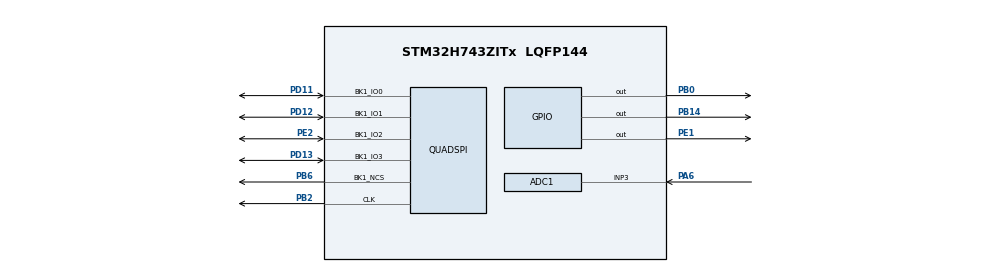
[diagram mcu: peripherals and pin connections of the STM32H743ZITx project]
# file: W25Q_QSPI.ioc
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ADC1.Channel-1\#ChannelRegularConversion=ADC_CHANNEL_3
ADC1.ClockPrescaler=ADC_CLOCK_ASYNC_DIV4
ADC1.NbrOfConversionFlag=1
ADC1.OffsetNumber-1\#ChannelRegularConversion=ADC_OFFSET_NONE
ADC1.OffsetSignedSaturation-1\#ChannelRegularConversion=DISABLE
ADC1.Rank-1\#ChannelRegularConversion=1
ADC1.Resolution=ADC_RESOLUTION_12B
ADC1.SamplingTime-1\#ChannelRegularConversion=ADC_SAMPLETIME_387CYCLES_5
ADC1.master=1
CORTEX_M7.AccessPermission_S-Cortex_Memory_Protection_Unit_Region1_Settings_S=MPU_REGION_FULL_ACCESS
CORTEX_M7.AccessPermission_Spec=MPU_REGION_FULL_ACCESS
CORTEX_M7.BaseAddress_S-Cortex_Memory_Protection_Unit_Region1_Settings_S=0x90000000
CORTEX_M7.BaseAddress_Spec=0x90000000
CORTEX_M7.CPU_DCache=Enabled
CORTEX_M7.CPU_ICache=Enabled
CORTEX_M7.Enable_S-Cortex_Memory_Protection_Unit_Region1_Settings_S=MPU_REGION_ENABLE
CORTEX_M7.IsBufferable_S-Cortex_Memory_Protection_Unit_Region1_Settings_S=MPU_ACCESS_BUFFERABLE
CORTEX_M7.IsBufferable_Spec=MPU_ACCESS_BUFFERABLE
CORTEX_M7.IsCacheable_S-Cortex_Memory_Protection_Unit_Region1_Settings_S=MPU_ACCESS_CACHEABLE
CORTEX_M7.IsCacheable_Spec=MPU_ACCESS_CACHEABLE
CORTEX_M7.IsShareable_Spec=MPU_ACCESS_NOT_SHAREABLE
CORTEX_M7.Size_S-Cortex_Memory_Protection_Unit_Region1_Settings_S=MPU_REGION_SIZE_1MB
CORTEX_M7.Size_Spec=MPU_REGION_SIZE_32MB
CORTEX_M7.SubRegionDisable_Spec=0
CORTEX_M7.default_mode_Activation=1
Mcu.Family=STM32H7
Mcu.Name=STM32H743ZITx
Mcu.Package=LQFP144
NUCLEO-H743ZI2.BUTTON=0
NUCLEO-H743ZI2.LD1=true
NUCLEO-H743ZI2.LD2=true
NUCLEO-H743ZI2.LD3=true
NUCLEO-H743ZI2.VCP=false
NVIC.PriorityGroup=NVIC_PRIORITYGROUP_4
PA13\ (JTMS/SWDIO).GPIO_Label=JTMS
PA13\ (JTMS/SWDIO).Signal=DEBUG_JTMS-SWDIO
PA14\ (JTCK/SWCLK).GPIO_Label=JTCK
PA14\ (JTCK/SWCLK).Signal=DEBUG_JTCK-SWCLK
PA6.Signal=ADCx_INP3
PB0.Signal=GPIO_Output
PB14.Signal=GPIO_Output
PB2.GPIO_Speed=GPIO_SPEED_FREQ_VERY_HIGH
PB2.Mode=Single Bank 1
PB2.Signal=QUADSPI_CLK
PB6.GPIO_Speed=GPIO_SPEED_FREQ_VERY_HIGH
PB6.Mode=Single Bank 1
PB6.Signal=QUADSPI_BK1_NCS
PC14-OSC32_IN\ (OSC32_IN).Signal=RCC_OSC32_IN
PC15-OSC32_OUT\ (OSC32_OUT).Signal=RCC_OSC32_OUT
PD11.GPIO_Speed=GPIO_SPEED_FREQ_VERY_HIGH
PD11.Mode=Single Bank 1
PD11.Signal=QUADSPI_BK1_IO0
PD12.GPIO_Speed=GPIO_SPEED_FREQ_VERY_HIGH
PD12.Mode=Single Bank 1
PD12.Signal=QUADSPI_BK1_IO1
PD13.GPIO_Speed=GPIO_SPEED_FREQ_VERY_HIGH
PD13.Mode=Single Bank 1
PD13.Signal=QUADSPI_BK1_IO3
PE1.Signal=GPIO_Output
PE2.GPIO_Speed=GPIO_SPEED_FREQ_VERY_HIGH
PE2.Mode=Single Bank 1
PE2.Signal=QUADSPI_BK1_IO2
PH0-OSC_IN\ (PH0).Mode=HSE-External-Oscillator
PH0-OSC_IN\ (PH0).Signal=RCC_OSC_IN
PH1-OSC_OUT\ (PH1).Mode=HSE-External-Oscillator
PH1-OSC_OUT\ (PH1).Signal=RCC_OSC_OUT
ProjectManager.HeapSize=0x200
ProjectManager.StackSize=0x400
ProjectManager.TargetToolchain=STM32CubeIDE
QUADSPI.ChipSelectHighTime=QSPI_CS_HIGH_TIME_1_CYCLE
QUADSPI.ClockPrescaler=1
QUADSPI.FifoThreshold=4
QUADSPI.FlashSize=24
QUADSPI.SampleShifting=QSPI_SAMPLE_SHIFTING_HALFCYCLE
RCC.ADCFreq_Value=75000000
RCC.APB1Freq_Value=100000000
RCC.APB2Freq_Value=100000000
RCC.APB3Freq_Value=100000000
RCC.APB4Freq_Value=100000000
RCC.CortexFreq_Value=400000000
RCC.D1PPRE=RCC_APB3_DIV2
RCC.D2PPRE1=RCC_APB1_DIV2
RCC.D2PPRE2=RCC_APB2_DIV2
RCC.D3PPRE=RCC_APB4_DIV2
RCC.DIVM1=2
RCC.DIVM2=2
RCC.DIVN1=64
RCC.DIVN2=12
RCC.DIVQ1=4
RCC.EnbaleCSS=true
RCC.HCLKFreq_Value=200000000
RCC.HPRE=RCC_HCLK_DIV2
RCC.PLL2FRACN=0
RCC.PLL3FRACN=0
RCC.PLLFRACN=0
RCC.PLLSourceVirtual=RCC_PLLSOURCE_HSE
RCC.SYSCLKFreq_VALUE=400000000
RCC.SYSCLKSource=RCC_SYSCLKSOURCE_PLLCLK
RCC.USBFreq_Value=200000000
SH.ADCx_INP3.0=ADC1_INP3,IN3-Single-Ended
VP_MEMORYMAP_VS_MEMORYMAP.Mode=CurAppReg
VP_NUCLEO-H743ZI2_VS_BSP_COMMON.Mode=COMMON
board=NUCLEO-H743ZI2

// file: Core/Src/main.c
/* USER CODE BEGIN Header */
/* USER CODE END Header */
#include "main.h"
#include "adc.h"
#include "quadspi.h"
#include "gpio.h"

/* USER CODE BEGIN Includes */
#include "quadspi.h"
/* USER CODE END Includes */

void SystemClock_Config(void);
static void MPU_Config(void);

/* USER CODE BEGIN 0 */

/////////////////////////////////////////////////////////////////////////////////////////////////////////////////////////////////
///////////////////////////////////////////////////// Memory Mapped testing /////////////////////////////////////////////////////
/////////////////////////////////////////////////////////////////////////////////////////////////////////////////////////////////

//const __attribute__((section(".extFlash"))) uint8_t buf[] = "Hello world from H743 QSPI";
//uint8_t readbuf[40];

/////////////////////////////////////////////////////////////////////////////////////////////////////////////////////////////////
////////////////////////////////////////////////////////// XiP testing //////////////////////////////////////////////////////////
/////////////////////////////////////////////////////////////////////////////////////////////////////////////////////////////////

//#define APPLICATION_ADDRESS 0x90000000U
//typedef void (*pFunction)(void);
//pFunction JumpToApplication;

/////////////////////////////////////////////////////////////////////////////////////////////////////////////////////////////////
/////////////////////////////////////////////////////////////////////////////////////////////////////////////////////////////////
/////////////////////////////////////////////////////////////////////////////////////////////////////////////////////////////////

/* USER CODE END 0 */

int main(void)
{

  /* MPU Configuration--------------------------------------------------------*/
  MPU_Config();

  /* Enable the CPU Cache */

  /* Enable I-Cache---------------------------------------------------------*/
  SCB_EnableICache();

  /* Enable D-Cache---------------------------------------------------------*/
  SCB_EnableDCache();

  /* MCU Configuration--------------------------------------------------------*/

  /* Reset of all peripherals, Initializes the Flash interface and the Systick. */
  HAL_Init();

  /* Configure the system clock */
  SystemClock_Config();

  /* Initialize all configured peripherals */
  MX_GPIO_Init();
  MX_QUADSPI_Init();
  MX_ADC1_Init();
  /* USER CODE BEGIN 2 */

  /////////////////////////////////////////////////////////////////////////////////////////////////////////////////////////////////
  ////////////////////////////////////////////////////////// XiP testing //////////////////////////////////////////////////////////
  /////////////////////////////////////////////////////////////////////////////////////////////////////////////////////////////////

//  if (QSPI_Set_Status_Config(&hqspi) != HAL_OK) Error_Handler();
//  if (QSPI_EnableMemoryMapped_1_4_4(&hqspi) != HAL_OK) Error_Handler();
//
//  SCB_DisableDCache();
//  SCB_DisableICache();
//
//  SysTick->CTRL = 0;
//
//  JumpToApplication = (pFunction) (*(__IO uint32_t*) (APPLICATION_ADDRESS + 4));
//  __set_MSP(*(__IO uint32_t*) APPLICATION_ADDRESS);
//  JumpToApplication();
//
  /* USER CODE END 2 */

  /* Initialize leds */
  BSP_LED_Init(LED_GREEN);
  BSP_LED_Init(LED_YELLOW);
  BSP_LED_Init(LED_RED);

  /* Infinite loop */
  /* USER CODE BEGIN WHILE */

  //////////////////////////////////////QSPI SELF TEST///////////////////////////////////

//  char test_string[] = "JULIAN";
//  const size_t string_len = sizeof(test_string) - 1;
//
//  if(QSPI_SelfTest(&hqspi, LOG_START_ADDR, test_string, string_len) == HAL_OK){
//      BSP_LED_Off(LED_RED);
//      BSP_LED_On(LED_GREEN);
//  }
//  else {
//      BSP_LED_On(LED_RED);
//      BSP_LED_Off(LED_GREEN);
//  }

  ///////////////////////////////////////////////////// Memory Mapped testing /////////////////////////////////////////////////////

//  if (QSPI_Set_Status_Config(&hqspi) != HAL_OK) Error_Handler();
//  if (QSPI_EnableMemoryMapped_1_4_4(&hqspi) != HAL_OK) Error_Handler();
//  memcpy(readbuf, buf, sizeof(buf));

  uint16_t val = 0;

  while (1)
  {
    /* USER CODE END WHILE */

    /* USER CODE BEGIN 3 */
	  HAL_Delay(50);
	  val = ReadPot();
  }
  /* USER CODE END 3 */
}

void SystemClock_Config(void)
{
  RCC_OscInitTypeDef RCC_OscInitStruct = {0};
  RCC_ClkInitTypeDef RCC_ClkInitStruct = {0};

  /** Supply configuration update enable
  */
  HAL_PWREx_ConfigSupply(PWR_LDO_SUPPLY);

  /** Configure the main internal regulator output voltage
  */
  __HAL_PWR_VOLTAGESCALING_CONFIG(PWR_REGULATOR_VOLTAGE_SCALE1);

  while(!__HAL_PWR_GET_FLAG(PWR_FLAG_VOSRDY)) {}

  /** Initializes the RCC Oscillators according to the specified parameters
  * in the RCC_OscInitTypeDef structure.
  */
  RCC_OscInitStruct.OscillatorType = RCC_OSCILLATORTYPE_HSE;
  RCC_OscInitStruct.HSEState = RCC_HSE_ON;
  RCC_OscInitStruct.PLL.PLLState = RCC_PLL_ON;
  RCC_OscInitStruct.PLL.PLLSource = RCC_PLLSOURCE_HSE;
  RCC_OscInitStruct.PLL.PLLM = 2;
  RCC_OscInitStruct.PLL.PLLN = 64;
  RCC_OscInitStruct.PLL.PLLP = 2;
  RCC_OscInitStruct.PLL.PLLQ = 4;
  RCC_OscInitStruct.PLL.PLLR = 2;
  RCC_OscInitStruct.PLL.PLLRGE = RCC_PLL1VCIRANGE_3;
  RCC_OscInitStruct.PLL.PLLVCOSEL = RCC_PLL1VCOWIDE;
  RCC_OscInitStruct.PLL.PLLFRACN = 0;
  if (HAL_RCC_OscConfig(&RCC_OscInitStruct) != HAL_OK)
  {
    Error_Handler();
  }

  /** Initializes the CPU, AHB and APB buses clocks
  */
  RCC_ClkInitStruct.ClockType = RCC_CLOCKTYPE_HCLK|RCC_CLOCKTYPE_SYSCLK
                              |RCC_CLOCKTYPE_PCLK1|RCC_CLOCKTYPE_PCLK2
                              |RCC_CLOCKTYPE_D3PCLK1|RCC_CLOCKTYPE_D1PCLK1;
  RCC_ClkInitStruct.SYSCLKSource = RCC_SYSCLKSOURCE_PLLCLK;
  RCC_ClkInitStruct.SYSCLKDivider = RCC_SYSCLK_DIV1;
  RCC_ClkInitStruct.AHBCLKDivider = RCC_HCLK_DIV2;
  RCC_ClkInitStruct.APB3CLKDivider = RCC_APB3_DIV2;
  RCC_ClkInitStruct.APB1CLKDivider = RCC_APB1_DIV2;
  RCC_ClkInitStruct.APB2CLKDivider = RCC_APB2_DIV2;
  RCC_ClkInitStruct.APB4CLKDivider = RCC_APB4_DIV2;

  if (HAL_RCC_ClockConfig(&RCC_ClkInitStruct, FLASH_LATENCY_2) != HAL_OK)
  {
    Error_Handler();
  }

  /** Enables the Clock Security System
  */
  HAL_RCC_EnableCSS();
}

 /* MPU Configuration */

void MPU_Config(void)
{
  MPU_Region_InitTypeDef MPU_InitStruct = {0};

  /* Disables the MPU */
  HAL_MPU_Disable();

  /** Initializes and configures the Region and the memory to be protected
  */
  MPU_InitStruct.Enable = MPU_REGION_ENABLE;
  MPU_InitStruct.Number = MPU_REGION_NUMBER0;
  MPU_InitStruct.BaseAddress = 0x90000000;
  MPU_InitStruct.Size = MPU_REGION_SIZE_32MB;
  MPU_InitStruct.SubRegionDisable = 0;
  MPU_InitStruct.TypeExtField = MPU_TEX_LEVEL0;
  MPU_InitStruct.AccessPermission = MPU_REGION_FULL_ACCESS;
  MPU_InitStruct.DisableExec = MPU_INSTRUCTION_ACCESS_DISABLE;
  MPU_InitStruct.IsShareable = MPU_ACCESS_NOT_SHAREABLE;
  MPU_InitStruct.IsCacheable = MPU_ACCESS_CACHEABLE;
  MPU_InitStruct.IsBufferable = MPU_ACCESS_BUFFERABLE;

  HAL_MPU_ConfigRegion(&MPU_InitStruct);

  /** Initializes and configures the Region and the memory to be protected
  */
  MPU_InitStruct.Number = MPU_REGION_NUMBER1;
  MPU_InitStruct.Size = MPU_REGION_SIZE_1MB;
  MPU_InitStruct.SubRegionDisable = 0x0;
  MPU_InitStruct.DisableExec = MPU_INSTRUCTION_ACCESS_ENABLE;

  HAL_MPU_ConfigRegion(&MPU_InitStruct);
  /* Enables the MPU */
  HAL_MPU_Enable(MPU_PRIVILEGED_DEFAULT);

}

void Error_Handler(void)
{
  /* USER CODE BEGIN Error_Handler_Debug */

  // Si ocurre un error en cualquier paso
  BSP_LED_Off(LED_GREEN);
  BSP_LED_Off(LED_YELLOW);
  BSP_LED_On(LED_RED); // Fallo: LED Rojo Encendido Fijo
  while(1){

  }
  /* USER CODE END Error_Handler_Debug */
}
